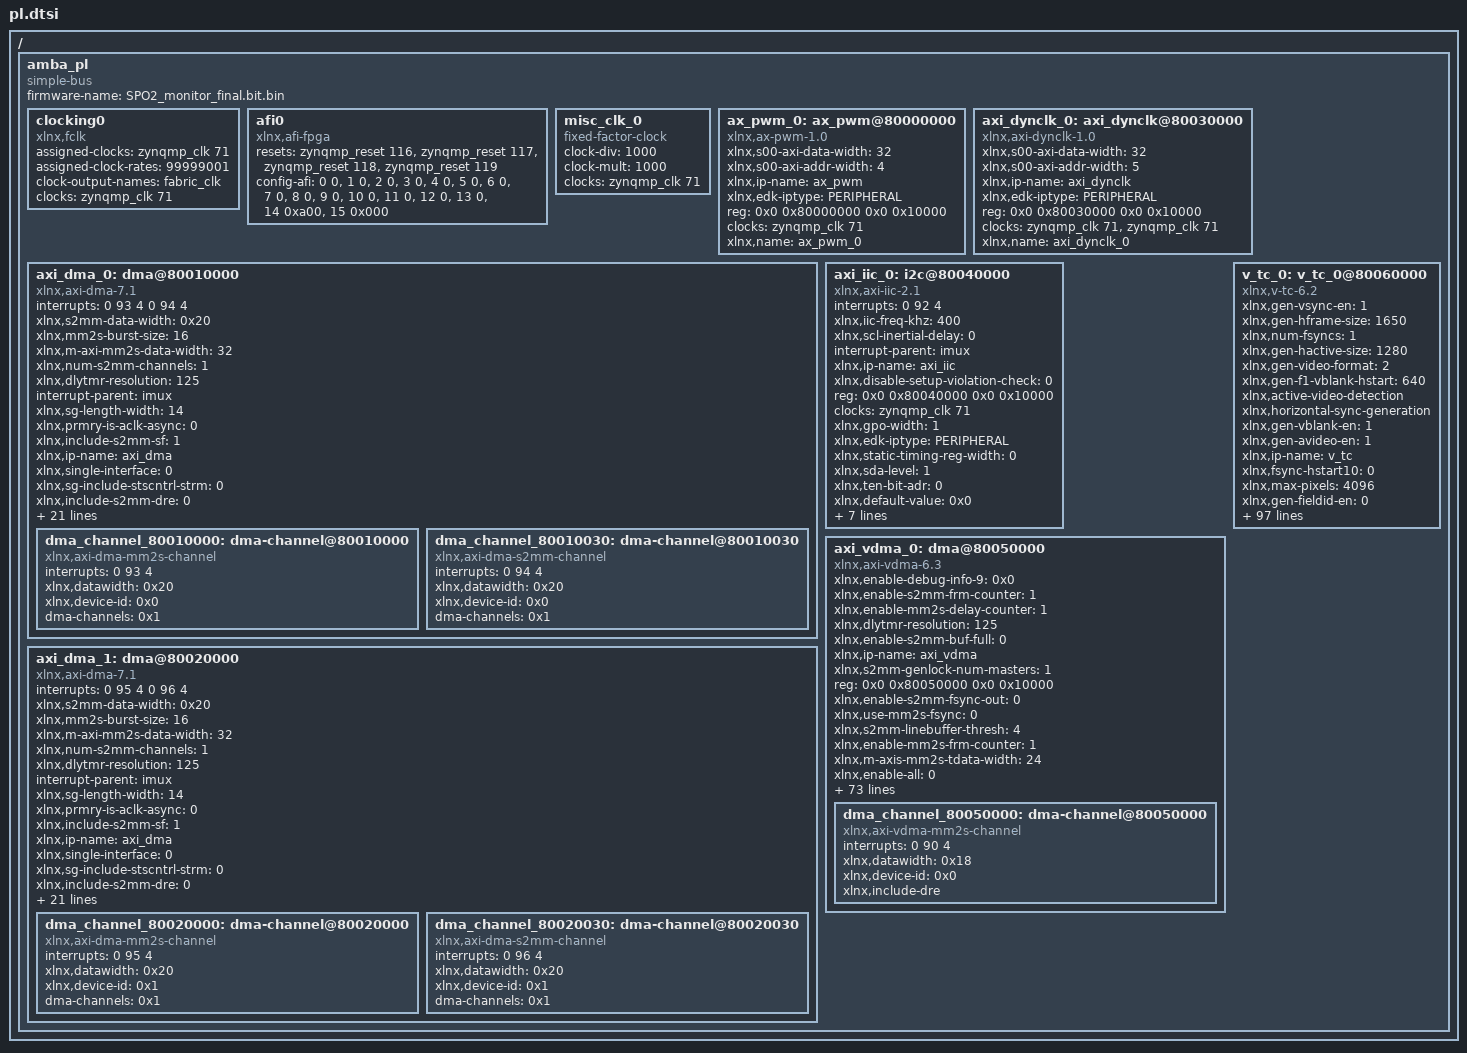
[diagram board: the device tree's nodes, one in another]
/ {
	amba_pl: amba_pl {
		ranges;
		compatible = "simple-bus";
		#address-cells = <2>;
		#size-cells = <2>;
		firmware-name = "SPO2_monitor_final.bit.bin";
		clocking0: clocking0 {
			compatible = "xlnx,fclk";
			status = "okay";
			assigned-clocks = <&zynqmp_clk 71>;
			assigned-clock-rates = <99999001>;
			#clock-cells = <0>;
			clock-output-names = "fabric_clk";
			clocks = <&zynqmp_clk 71>;
		};
		afi0: afi0 {
			status = "okay";
			compatible = "xlnx,afi-fpga";
			resets = <&zynqmp_reset 116>, <&zynqmp_reset 117>, <&zynqmp_reset 118>, <&zynqmp_reset 119>;
			config-afi = < 0 0>, <1 0>, <2 0>, <3 0>, <4 0>, <5 0>, <6 0>, <7 0>, <8 0>, <9 0>, <10 0>, <11 0>, <12 0>, <13 0>, <14 0xa00>, <15 0x000>;
		};
		misc_clk_0: misc_clk_0 {
			clock-div = <1000>;
			compatible = "fixed-factor-clock";
			clock-mult = <1000>;
			clocks = <&zynqmp_clk 71>;
			#clock-cells = <0>;
		};
		ax_pwm_0: ax_pwm@80000000 {
			xlnx,s00-axi-data-width = <32>;
			compatible = "xlnx,ax-pwm-1.0";
			status = "okay";
			clock-names = "s00_axi_aclk";
			xlnx,s00-axi-addr-width = <4>;
			xlnx,ip-name = "ax_pwm";
			xlnx,edk-iptype = "PERIPHERAL";
			reg = <0x0 0x80000000 0x0 0x10000>;
			clocks = <&zynqmp_clk 71>;
			xlnx,name = "ax_pwm_0";
		};
		axi_dma_0: dma@80010000 {
			interrupts = < 0 93 4 0 94 4 >;
			compatible = "xlnx,axi-dma-7.1" , "xlnx,axi-dma-1.00.a";
			xlnx,s2mm-data-width = <0x20>;
			xlnx,mm2s-burst-size = <16>;
			xlnx,m-axi-mm2s-data-width = <32>;
			xlnx,num-s2mm-channels = <1>;
			xlnx,dlytmr-resolution = <125>;
			interrupt-parent = <&imux>;
			xlnx,sg-length-width = <14>;
			xlnx,prmry-is-aclk-async = <0>;
			xlnx,include-s2mm-sf = <1>;
			#dma-cells = <1>;
			xlnx,ip-name = "axi_dma";
			xlnx,single-interface = <0>;
			xlnx,sg-include-stscntrl-strm = <0>;
			xlnx,include-s2mm-dre = <0>;
			reg = <0x0 0x80010000 0x0 0x10000>;
			xlnx,addr-width = <32>;
			xlnx,include-s2mm = <1>;
			clocks = <&zynqmp_clk 71>, <&zynqmp_clk 71>, <&zynqmp_clk 71>;
			xlnx,s-axis-s2mm-tdata-width = <32>;
			xlnx,micro-dma = <0>;
			xlnx,increase-throughput = <0>;
			xlnx,mm2s-data-width = <0x20>;
			xlnx,addrwidth = <0x20>;
			xlnx,sg-use-stsapp-length = <0>;
			xlnx,m-axis-mm2s-tdata-width = <32>;
			xlnx,edk-iptype = "PERIPHERAL";
			xlnx,s2mm-burst-size = <16>;
			xlnx,m-axi-s2mm-data-width = <32>;
			xlnx,num-mm2s-channels = <1>;
			xlnx,enable-multi-channel = <0>;
			status = "okay";
			xlnx,include-mm2s-sf = <1>;
			clock-names = "m_axi_mm2s_aclk" , "m_axi_s2mm_aclk" , "s_axi_lite_aclk";
			interrupt-names = "mm2s_introut" , "s2mm_introut";
			xlnx,include-mm2s = <1>;
			xlnx,include-mm2s-dre = <0>;
			xlnx,name = "axi_dma_0";
			dma_channel_80010000: dma-channel@80010000 {
				interrupts = <0 93 4>;
				xlnx,datawidth = <0x20>;
				xlnx,device-id = <0x0>;
				compatible = "xlnx,axi-dma-mm2s-channel";
				dma-channels = <0x1>;
			};
			dma_channel_80010030: dma-channel@80010030 {
				interrupts = <0 94 4>;
				xlnx,datawidth = <0x20>;
				xlnx,device-id = <0x0>;
				compatible = "xlnx,axi-dma-s2mm-channel";
				dma-channels = <0x1>;
			};
		};
		axi_dma_1: dma@80020000 {
			interrupts = < 0 95 4 0 96 4 >;
			compatible = "xlnx,axi-dma-7.1" , "xlnx,axi-dma-1.00.a";
			xlnx,s2mm-data-width = <0x20>;
			xlnx,mm2s-burst-size = <16>;
			xlnx,m-axi-mm2s-data-width = <32>;
			xlnx,num-s2mm-channels = <1>;
			xlnx,dlytmr-resolution = <125>;
			interrupt-parent = <&imux>;
			xlnx,sg-length-width = <14>;
			xlnx,prmry-is-aclk-async = <0>;
			xlnx,include-s2mm-sf = <1>;
			#dma-cells = <1>;
			xlnx,ip-name = "axi_dma";
			xlnx,single-interface = <0>;
			xlnx,sg-include-stscntrl-strm = <0>;
			xlnx,include-s2mm-dre = <0>;
			reg = <0x0 0x80020000 0x0 0x10000>;
			xlnx,addr-width = <32>;
			xlnx,include-s2mm = <1>;
			clocks = <&zynqmp_clk 71>, <&zynqmp_clk 71>, <&zynqmp_clk 71>;
			xlnx,s-axis-s2mm-tdata-width = <32>;
			xlnx,micro-dma = <0>;
			xlnx,increase-throughput = <0>;
			xlnx,mm2s-data-width = <0x20>;
			xlnx,addrwidth = <0x20>;
			xlnx,sg-use-stsapp-length = <0>;
			xlnx,m-axis-mm2s-tdata-width = <32>;
			xlnx,edk-iptype = "PERIPHERAL";
			xlnx,s2mm-burst-size = <16>;
			xlnx,m-axi-s2mm-data-width = <32>;
			xlnx,num-mm2s-channels = <1>;
			xlnx,enable-multi-channel = <0>;
			status = "okay";
			xlnx,include-mm2s-sf = <1>;
			clock-names = "m_axi_mm2s_aclk" , "m_axi_s2mm_aclk" , "s_axi_lite_aclk";
			interrupt-names = "mm2s_introut" , "s2mm_introut";
			xlnx,include-mm2s = <1>;
			xlnx,include-mm2s-dre = <0>;
			xlnx,name = "axi_dma_1";
			dma_channel_80020000: dma-channel@80020000 {
				interrupts = <0 95 4>;
				xlnx,datawidth = <0x20>;
				xlnx,device-id = <0x1>;
				compatible = "xlnx,axi-dma-mm2s-channel";
				dma-channels = <0x1>;
			};
			dma_channel_80020030: dma-channel@80020030 {
				interrupts = <0 96 4>;
				xlnx,datawidth = <0x20>;
				xlnx,device-id = <0x1>;
				compatible = "xlnx,axi-dma-s2mm-channel";
				dma-channels = <0x1>;
			};
		};
		axi_dynclk_0: axi_dynclk@80030000 {
			xlnx,s00-axi-data-width = <32>;
			compatible = "xlnx,axi-dynclk-1.0";
			status = "okay";
			clock-names = "REF_CLK_I" , "s00_axi_aclk";
			xlnx,s00-axi-addr-width = <5>;
			xlnx,ip-name = "axi_dynclk";
			xlnx,edk-iptype = "PERIPHERAL";
			reg = <0x0 0x80030000 0x0 0x10000>;
			clocks = <&zynqmp_clk 71>, <&zynqmp_clk 71>;
			xlnx,name = "axi_dynclk_0";
		};
		axi_iic_0: i2c@80040000 {
			interrupts = < 0 92 4 >;
			xlnx,iic-freq-khz = <400>;
			compatible = "xlnx,axi-iic-2.1" , "xlnx,xps-iic-2.00.a";
			xlnx,scl-inertial-delay = <0>;
			interrupt-parent = <&imux>;
			xlnx,ip-name = "axi_iic";
			xlnx,disable-setup-violation-check = <0>;
			reg = <0x0 0x80040000 0x0 0x10000>;
			clocks = <&zynqmp_clk 71>;
			xlnx,gpo-width = <1>;
			xlnx,edk-iptype = "PERIPHERAL";
			xlnx,static-timing-reg-width = <0>;
			xlnx,sda-level = <1>;
			status = "okay";
			clock-names = "s_axi_aclk";
			xlnx,ten-bit-adr = <0>;
			xlnx,default-value = <0x0>;
			interrupt-names = "iic2intc_irpt";
			xlnx,iic-board-interface = "Custom";
			xlnx,timing-reg-width = <32>;
			xlnx,iic-freq = <400000>;
			xlnx,smbus-pmbus-host = <0>;
			xlnx,name = "axi_iic_0";
			xlnx,axi-aclk-freq-mhz = <0x5f5dd19>;
			xlnx,sda-inertial-delay = <0>;
		};
		axi_vdma_0: dma@80050000 {
			xlnx,enable-debug-info-9 = <0x0>;
			xlnx,enable-s2mm-frm-counter = <1>;
			xlnx,enable-mm2s-delay-counter = <1>;
			xlnx,dlytmr-resolution = <125>;
			xlnx,enable-s2mm-buf-full = <0>;
			xlnx,ip-name = "axi_vdma";
			xlnx,s2mm-genlock-num-masters = <1>;
			reg = <0x0 0x80050000 0x0 0x10000>;
			xlnx,enable-s2mm-fsync-out = <0>;
			xlnx,use-mm2s-fsync = <0>;
			xlnx,s2mm-linebuffer-thresh = <4>;
			xlnx,enable-mm2s-frm-counter = <1>;
			xlnx,m-axis-mm2s-tdata-width = <24>;
			xlnx,enable-all = <0>;
			xlnx,dynamic-resolution = <1>;
			xlnx,enable-s2mm-rst-out = <0>;
			interrupt-names = "mm2s_introut";
			xlnx,s2mm-sof-enable = <0x1>;
			xlnx,mm2s-genlock-num-masters = <1>;
			xlnx,enable-mm2s-fsync-out = <0>;
			xlnx,mm2s-linebuffer-thresh = <4>;
			compatible = "xlnx,axi-vdma-6.3" , "xlnx,axi-vdma-1.00.a";
			xlnx,enable-tstvec = <0>;
			interrupt-parent = <&imux>;
			xlnx,s2mm-max-burst-length = <8>;
			xlnx,enable-mm2s-rst-out = <0>;
			xlnx,mm2s-sof-enable = <1>;
			xlnx,include-s2mm-dre = <0x0>;
			xlnx,enable-s2mm-frmstr-reg = <0>;
			xlnx,m-axi-s2mm-data-width = <64>;
			xlnx,enable-s2mm-sts-reg = <0>;
			xlnx,mm2s-max-burst-length = <32>;
			status = "okay";
			xlnx,include-mm2s-dre = <0x1>;
			xlnx,name = "axi_vdma_0";
			xlnx,enable-mm2s-frmstr-reg = <0>;
			interrupts = < 0 90 4 >;
			xlnx,m-axi-mm2s-data-width = <64>;
			xlnx,flush-on-fsync = <0x1>;
			xlnx,include-s2mm-sf = <1>;
			xlnx,single-interface = <0>;
			xlnx,s2mm-linebuffer-depth = <0x200>;
			xlnx,include-s2mm = <0x0>;
			xlnx,addr-width = <64>;
			clocks = <&zynqmp_clk 72>, <&zynqmp_clk 72>, <&zynqmp_clk 71>;
			xlnx,s-axis-s2mm-tdata-width = <32>;
			xlnx,enable-debug-info-10 = <0>;
			xlnx,addrwidth = <0x40>;
			xlnx,enable-debug-info-11 = <0>;
			xlnx,edk-iptype = "PERIPHERAL";
			xlnx,enable-debug-info-12 = <0>;
			xlnx,use-fsync = <1>;
			xlnx,s2mm-genlock-repeat-en = <1>;
			xlnx,enable-debug-info-13 = <0x0>;
			xlnx,enable-vert-flip = <0x0>;
			xlnx,include-mm2s-sf = <0>;
			xlnx,enable-debug-info-14 = <0x1>;
			xlnx,include-internal-genlock = <0x1>;
			clock-names = "m_axi_mm2s_aclk" , "m_axis_mm2s_aclk" , "s_axi_lite_aclk";
			xlnx,enable-debug-info-15 = <0x1>;
			xlnx,mm2s-linebuffer-depth = <0x200>;
			xlnx,include-mm2s = <0x1>;
			xlnx,s2mm-genlock-mode = <0x0>;
			xlnx,flush-fsync = <0x1>;
			xlnx,select-xpm = <0>;
			xlnx,s2mm-data-width = <0x40>;
			xlnx,num-fstores = <0x3>;
			xlnx,enable-s2mm-param-updt = <0>;
			xlnx,enable-vidparam-reads = <0x1>;
			xlnx,mm2s-genlock-repeat-en = <0>;
			xlnx,prmry-is-aclk-async = <0>;
			xlnx,s2mm-tdata-width = <0x20>;
			#dma-cells = <1>;
			xlnx,enable-vidprmtr-reads = <1>;
			xlnx,mm2s-genlock-mode = <0x0>;
			xlnx,enable-debug-info-0 = <0>;
			xlnx,enable-debug-all = <0x0>;
			xlnx,enable-debug-info-1 = <0x0>;
			xlnx,mm2s-data-width = <0x40>;
			xlnx,enable-debug-info-2 = <0>;
			xlnx,enable-mm2s-param-updt = <0>;
			xlnx,enable-debug-info-3 = <0>;
			xlnx,enable-s2mm-delay-counter = <1>;
			xlnx,enable-debug-info-4 = <0>;
			xlnx,enable-debug-info-5 = <0x0>;
			xlnx,mm2s-tdata-width = <0x18>;
			xlnx,enable-debug-info-6 = <0x1>;
			xlnx,enable-debug-info-7 = <0x1>;
			xlnx,use-s2mm-fsync = <2>;
			xlnx,enable-debug-info-8 = <0>;
			xlnx,enable-mm2s-buf-empty = <0>;
			dma_channel_80050000: dma-channel@80050000 {
				interrupts = < 0 90 4 >;
				xlnx,datawidth = <0x18>;
				xlnx,device-id = <0x0>;
				compatible = "xlnx,axi-vdma-mm2s-channel";
				xlnx,include-dre;
			};
		};
		v_tc_0: v_tc_0@80060000 {
			xlnx,gen-vsync-en = <1>;
			xlnx,gen-hframe-size = <1650>;
			xlnx,num-fsyncs = <1>;
			xlnx,gen-hactive-size = <1280>;
			xlnx,gen-video-format = <2>;
			xlnx,gen-f1-vblank-hstart = <640>;
			xlnx,active-video-detection;
			xlnx,horizontal-sync-generation;
			xlnx,gen-vblank-en = <1>;
			xlnx,gen-avideo-en = <1>;
			xlnx,ip-name = "v_tc";
			xlnx,fsync-hstart10 = <0>;
			xlnx,max-pixels = <4096>;
			xlnx,gen-fieldid-en = <0>;
			reg = <0x0 0x80060000 0x0 0x10000>;
			xlnx,det-vblank-en = <1>;
			xlnx,fsync-hstart11 = <0>;
			xlnx,fsync-hstart12 = <0>;
			xlnx,pixels-per-clock = <0x4>;
			xlnx,gen-interlaced = <0>;
			xlnx,det-avideo-en = <1>;
			xlnx,fsync-hstart13 = <0>;
			xlnx,fsync-hstart14 = <0>;
			xlnx,gen-f0-vblank-hend = <640>;
			xlnx,fsync-hstart15 = <0>;
			xlnx,det-hsync-en = <1>;
			interrupt-names = "irq";
			xlnx,enable-generation;
			xlnx,gen-avideo-polarity = <1>;
			xlnx,max-lines-per-frame = <4096>;
			xlnx,has-axi4-lite = <1>;
			compatible = "xlnx,v-tc-6.2" , "xlnx,bridge-v-tc-6.1";
			xlnx,max-clocks-per-line = <4096>;
			xlnx,gen-f0-vframe-size = <750>;
			xlnx,gen-f0-vblank-hstart = <640>;
			interrupt-parent = <&imux>;
			xlnx,max-lines = <4096>;
			xlnx,gen-f0-vsync-vstart = <724>;
			xlnx,horizontal-blank-generation;
			xlnx,gen-hsync-end = <1430>;
			xlnx,gen-f0-vsync-hstart = <640>;
			xlnx,gen-f1-vsync-hend = <695>;
			xlnx,vertical-blank-detection;
			xlnx,gen-vsync-polarity = <1>;
			xlnx,fsync-vstart0 = <0>;
			xlnx,gen-hsync-polarity = <1>;
			xlnx,fsync-vstart1 = <0>;
			status = "okay";
			xlnx,fsync-vstart2 = <0>;
			xlnx,gen-hsync-start = <1390>;
			xlnx,gen-f0-vsync-vend = <729>;
			xlnx,fsync-vstart3 = <0>;
			xlnx,vertical-sync-detection;
			xlnx,frame-syncs = <1>;
			xlnx,fsync-vstart4 = <0>;
			xlnx,gen-vactive-size = <720>;
			xlnx,name = "v_tc_0";
			xlnx,fsync-vstart5 = <0>;
			interrupts = < 0 89 4 >;
			xlnx,gen-achroma-en = <0>;
			xlnx,fsync-vstart6 = <0>;
			xlnx,det-fieldid-en = <0>;
			xlnx,fsync-vstart7 = <0>;
			xlnx,gen-hsync-en = <1>;
			xlnx,fsync-vstart8 = <0>;
			xlnx,fsync-vstart10 = <0>;
			xlnx,fsync-vstart9 = <0>;
			xlnx,fsync-vstart11 = <0>;
			xlnx,arbitrary-res-en = /bits/ 8 <0x0>;
			xlnx,fsync-vstart12 = <0>;
			xlnx,fsync-vstart13 = <0>;
			clocks = <&misc_clk_0>, <&zynqmp_clk 71>;
			xlnx,fsync-vstart14 = <0>;
			xlnx,fsync-vstart15 = <0>;
			xlnx,gen-cparity = <0>;
			xlnx,edk-iptype = "PERIPHERAL";
			xlnx,vertical-sync-generation;
			xlnx,gen-f1-vblank-hend = <640>;
			xlnx,det-vsync-en = <1>;
			xlnx,gen-vblank-polarity = <1>;
			xlnx,fsync-hstart0 = <0>;
			clock-names = "clk" , "s_axi_aclk";
			xlnx,interlace-en = <0>;
			xlnx,gen-auto-switch = <0>;
			xlnx,fsync-hstart1 = <0>;
			xlnx,fsync-hstart2 = <0>;
			xlnx,active-video-generation;
			xlnx,fsync-hstart3 = <0>;
			xlnx,fsync-hstart4 = <0>;
			xlnx,horizontal-blank-detection;
			xlnx,fsync-hstart5 = <0>;
			xlnx,gen-f1-vframe-size = <750>;
			xlnx,fsync-hstart6 = <0>;
			xlnx,fsync-hstart7 = <0>;
			xlnx,fsync-hstart8 = <0>;
			xlnx,gen-hblank-en = <1>;
			xlnx,fsync-hstart9 = <0>;
			xlnx,horizontal-sync-detection;
			xlnx,gen-f1-vsync-vend = <729>;
			xlnx,detect-en = <0>;
			xlnx,det-hblank-en = <1>;
			xlnx,vid-ppc = <4>;
			xlnx,has-intc-if = <0>;
			xlnx,generate-en = <1>;
			xlnx,gen-achroma-polarity = <1>;
			xlnx,sync-en = <0>;
			xlnx,det-achroma-en = <0>;
			xlnx,generator;
			xlnx,gen-f1-vsync-vstart = <724>;
			xlnx,vertical-blank-generation;
			xlnx,gen-hblank-polarity = <1>;
			xlnx,video-mode = "720p";
			xlnx,gen-fieldid-polarity = <1>;
			xlnx,gen-f1-vsync-hstart = <695>;
			xlnx,gen-f0-vsync-hend = <695>;
		};
	};
};
